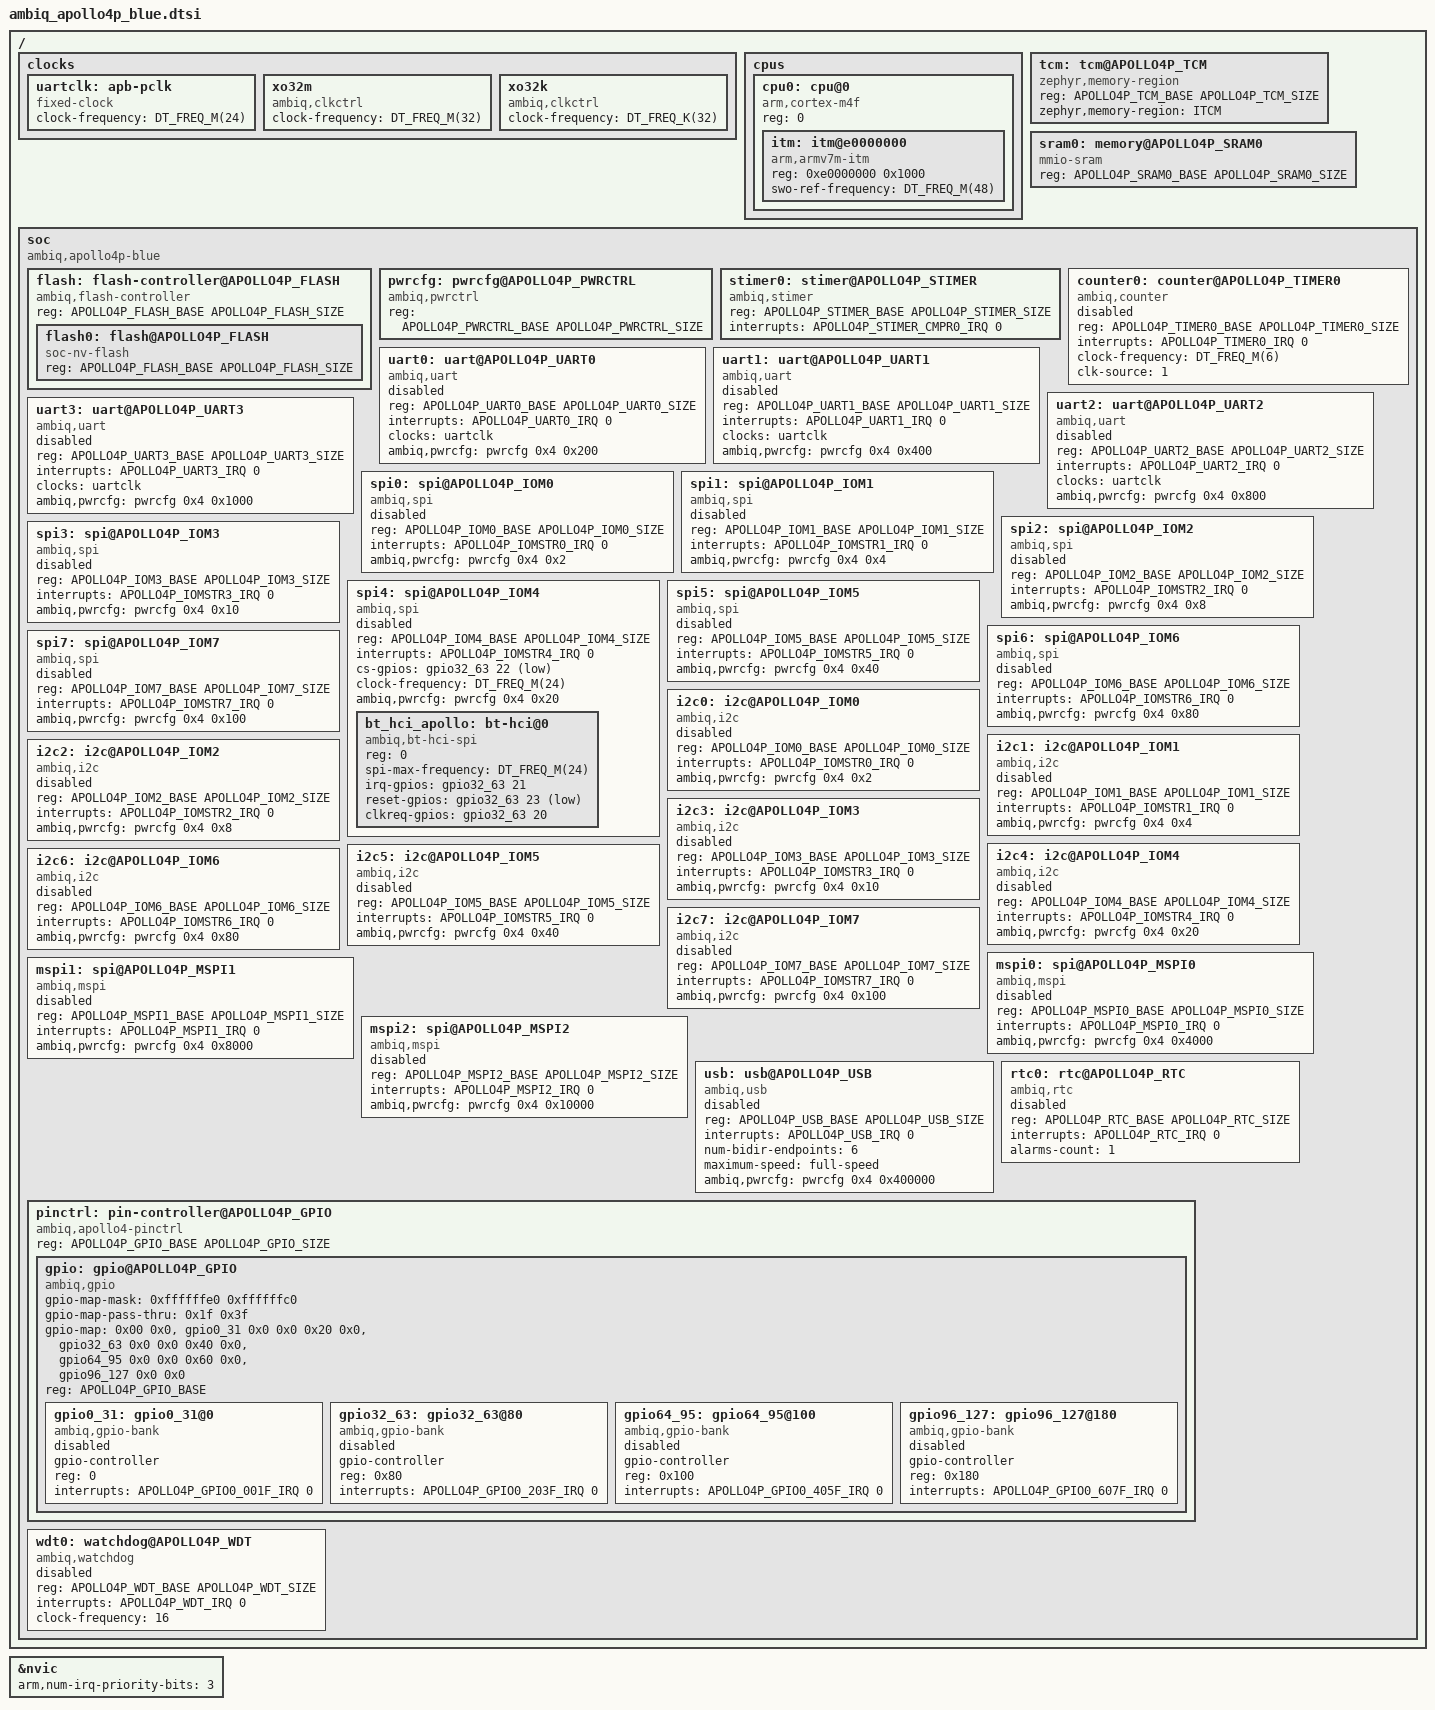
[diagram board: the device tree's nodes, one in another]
/* SPDX-License-Identifier: Apache-2.0 */

#include <arm/armv7-m.dtsi>
#include <mem.h>
#include <freq.h>
#include <apollo4p/am_apollo4p.h>
#include <zephyr/dt-bindings/i2c/i2c.h>
#include <zephyr/dt-bindings/gpio/gpio.h>

/ {
	clocks {
		uartclk: apb-pclk {
			compatible = "fixed-clock";
			clock-frequency = <DT_FREQ_M(24)>;
			#clock-cells = <0>;
		};
		xo32m: xo32m {
			compatible = "ambiq,clkctrl";
			clock-frequency = <DT_FREQ_M(32)>;
			#clock-cells = <1>;
		};
		xo32k: xo32k {
			compatible = "ambiq,clkctrl";
			clock-frequency = <DT_FREQ_K(32)>;
			#clock-cells = <1>;
		};
	};

	cpus {
		#address-cells = <1>;
		#size-cells = <0>;

		cpu0: cpu@0 {
			compatible = "arm,cortex-m4f";
			reg = <0>;
			#address-cells = <1>;
			#size-cells = <1>;

			itm: itm@e0000000 {
				compatible = "arm,armv7m-itm";
				reg = <0xe0000000 0x1000>;
				swo-ref-frequency = <DT_FREQ_M(48)>;
			};
		};
	};

	/* TCM */
	tcm: tcm@APOLLO4P_TCM {
		compatible = "zephyr,memory-region";
		reg = <APOLLO4P_TCM_BASE APOLLO4P_TCM_SIZE>;
		zephyr,memory-region = "ITCM";
	};

	/* SRAM */
	sram0: memory@APOLLO4P_SRAM0 {
		compatible = "mmio-sram";
		reg = <APOLLO4P_SRAM0_BASE APOLLO4P_SRAM0_SIZE>;
	};

	soc {
		compatible = "ambiq,apollo4p-blue", "ambiq,apollo4x", "simple-bus";

		flash: flash-controller@APOLLO4P_FLASH {
			compatible = "ambiq,flash-controller";
			reg = <APOLLO4P_FLASH_BASE APOLLO4P_FLASH_SIZE>;

			#address-cells = <1>;
			#size-cells = <1>;

			/* MRAM region */
			flash0: flash@APOLLO4P_FLASH {
				compatible = "soc-nv-flash";
				reg = <APOLLO4P_FLASH_BASE APOLLO4P_FLASH_SIZE>;
			};
		};

		pwrcfg: pwrcfg@APOLLO4P_PWRCTRL {
			compatible = "ambiq,pwrctrl";
			reg = <APOLLO4P_PWRCTRL_BASE APOLLO4P_PWRCTRL_SIZE>;
			#pwrcfg-cells = <2>;
		};

		stimer0: stimer@APOLLO4P_STIMER {
			compatible = "ambiq,stimer";
			reg = <APOLLO4P_STIMER_BASE APOLLO4P_STIMER_SIZE>;
			interrupts = <APOLLO4P_STIMER_CMPR0_IRQ 0>;
			status = "okay";
		};

		counter0: counter@APOLLO4P_TIMER0 {
			compatible = "ambiq,counter";
			reg = <APOLLO4P_TIMER0_BASE APOLLO4P_TIMER0_SIZE>;
			interrupts = <APOLLO4P_TIMER0_IRQ 0>;
			clock-frequency = <DT_FREQ_M(6)>;
			clk-source = <1>;
			status = "disabled";
		};

		uart0: uart@APOLLO4P_UART0 {
			compatible = "ambiq,uart", "arm,pl011";
			reg = <APOLLO4P_UART0_BASE APOLLO4P_UART0_SIZE>;
			interrupts = <APOLLO4P_UART0_IRQ 0>;
			interrupt-names = "UART0";
			status = "disabled";
			clocks = <&uartclk>;
			ambiq,pwrcfg = <&pwrcfg 0x4 0x200>;
		};
		uart1: uart@APOLLO4P_UART1 {
			compatible = "ambiq,uart", "arm,pl011";
			reg = <APOLLO4P_UART1_BASE APOLLO4P_UART1_SIZE>;
			interrupts = <APOLLO4P_UART1_IRQ 0>;
			interrupt-names = "UART1";
			status = "disabled";
			clocks = <&uartclk>;
			ambiq,pwrcfg = <&pwrcfg 0x4 0x400>;
		};

		uart2: uart@APOLLO4P_UART2 {
			compatible = "ambiq,uart", "arm,pl011";
			reg = <APOLLO4P_UART2_BASE APOLLO4P_UART2_SIZE>;
			interrupts = <APOLLO4P_UART2_IRQ 0>;
			interrupt-names = "UART2";
			status = "disabled";
			clocks = <&uartclk>;
			ambiq,pwrcfg = <&pwrcfg 0x4 0x800>;
		};

		uart3: uart@APOLLO4P_UART3 {
			compatible = "ambiq,uart", "arm,pl011";
			reg = <APOLLO4P_UART3_BASE APOLLO4P_UART3_SIZE>;
			interrupts = <APOLLO4P_UART3_IRQ 0>;
			interrupt-names = "UART3";
			status = "disabled";
			clocks = <&uartclk>;
			ambiq,pwrcfg = <&pwrcfg 0x4 0x1000>;
		};

		spi0: spi@APOLLO4P_IOM0 {
			compatible = "ambiq,spi";
			reg = <APOLLO4P_IOM0_BASE APOLLO4P_IOM0_SIZE>;
			#address-cells = <1>;
			#size-cells = <0>;
			interrupts = <APOLLO4P_IOMSTR0_IRQ 0>;
			status = "disabled";
			ambiq,pwrcfg = <&pwrcfg 0x4 0x2>;
		};

		spi1: spi@APOLLO4P_IOM1 {
			compatible = "ambiq,spi";
			reg = <APOLLO4P_IOM1_BASE APOLLO4P_IOM1_SIZE>;
			#address-cells = <1>;
			#size-cells = <0>;
			interrupts = <APOLLO4P_IOMSTR1_IRQ 0>;
			status = "disabled";
			ambiq,pwrcfg = <&pwrcfg 0x4 0x4>;
		};

		spi2: spi@APOLLO4P_IOM2 {
			compatible = "ambiq,spi";
			reg = <APOLLO4P_IOM2_BASE APOLLO4P_IOM2_SIZE>;
			#address-cells = <1>;
			#size-cells = <0>;
			interrupts = <APOLLO4P_IOMSTR2_IRQ 0>;
			status = "disabled";
			ambiq,pwrcfg = <&pwrcfg 0x4 0x8>;
		};

		spi3: spi@APOLLO4P_IOM3 {
			compatible = "ambiq,spi";
			reg = <APOLLO4P_IOM3_BASE APOLLO4P_IOM3_SIZE>;
			#address-cells = <1>;
			#size-cells = <0>;
			interrupts = <APOLLO4P_IOMSTR3_IRQ 0>;
			status = "disabled";
			ambiq,pwrcfg = <&pwrcfg 0x4 0x10>;
		};

		spi4: spi@APOLLO4P_IOM4 {
			/* IOM4 works as SPI and is wired internally for BLE HCI. */
			compatible = "ambiq,spi";
			reg = <APOLLO4P_IOM4_BASE APOLLO4P_IOM4_SIZE>;
			#address-cells = <1>;
			#size-cells = <0>;
			interrupts = <APOLLO4P_IOMSTR4_IRQ 0>;
			cs-gpios = <&gpio32_63 22 (GPIO_ACTIVE_LOW | GPIO_PULL_UP)>;
			clock-frequency = <DT_FREQ_M(24)>;
			status = "disabled";
			ambiq,pwrcfg = <&pwrcfg 0x4 0x20>;

			bt_hci_apollo: bt-hci@0 {
				compatible = "ambiq,bt-hci-spi";
				reg = <0>;
				spi-max-frequency = <DT_FREQ_M(24)>;
				irq-gpios = <&gpio32_63 21 GPIO_ACTIVE_HIGH>;
				reset-gpios = <&gpio32_63 23 GPIO_ACTIVE_LOW>;
				clkreq-gpios = <&gpio32_63 20 GPIO_ACTIVE_HIGH>;
			};
		};

		spi5: spi@APOLLO4P_IOM5 {
			compatible = "ambiq,spi";
			reg = <APOLLO4P_IOM5_BASE APOLLO4P_IOM5_SIZE>;
			#address-cells = <1>;
			#size-cells = <0>;
			interrupts = <APOLLO4P_IOMSTR5_IRQ 0>;
			status = "disabled";
			ambiq,pwrcfg = <&pwrcfg 0x4 0x40>;
		};

		spi6: spi@APOLLO4P_IOM6 {
			compatible = "ambiq,spi";
			reg = <APOLLO4P_IOM6_BASE APOLLO4P_IOM6_SIZE>;
			#address-cells = <1>;
			#size-cells = <0>;
			interrupts = <APOLLO4P_IOMSTR6_IRQ 0>;
			status = "disabled";
			ambiq,pwrcfg = <&pwrcfg 0x4 0x80>;
		};

		spi7: spi@APOLLO4P_IOM7 {
			compatible = "ambiq,spi";
			reg = <APOLLO4P_IOM7_BASE APOLLO4P_IOM7_SIZE>;
			#address-cells = <1>;
			#size-cells = <0>;
			interrupts = <APOLLO4P_IOMSTR7_IRQ 0>;
			status = "disabled";
			ambiq,pwrcfg = <&pwrcfg 0x4 0x100>;
		};

		i2c0: i2c@APOLLO4P_IOM0 {
			compatible = "ambiq,i2c";
			reg = <APOLLO4P_IOM0_BASE APOLLO4P_IOM0_SIZE>;
			#address-cells = <1>;
			#size-cells = <0>;
			interrupts = <APOLLO4P_IOMSTR0_IRQ 0>;
			status = "disabled";
			ambiq,pwrcfg = <&pwrcfg 0x4 0x2>;
		};

		i2c1: i2c@APOLLO4P_IOM1 {
			compatible = "ambiq,i2c";
			reg = <APOLLO4P_IOM1_BASE APOLLO4P_IOM1_SIZE>;
			#address-cells = <1>;
			#size-cells = <0>;
			interrupts = <APOLLO4P_IOMSTR1_IRQ 0>;
			status = "disabled";
			ambiq,pwrcfg = <&pwrcfg 0x4 0x4>;
		};

		i2c2: i2c@APOLLO4P_IOM2 {
			compatible = "ambiq,i2c";
			reg = <APOLLO4P_IOM2_BASE APOLLO4P_IOM2_SIZE>;
			#address-cells = <1>;
			#size-cells = <0>;
			interrupts = <APOLLO4P_IOMSTR2_IRQ 0>;
			status = "disabled";
			ambiq,pwrcfg = <&pwrcfg 0x4 0x8>;
		};

		i2c3: i2c@APOLLO4P_IOM3 {
			compatible = "ambiq,i2c";
			reg = <APOLLO4P_IOM3_BASE APOLLO4P_IOM3_SIZE>;
			#address-cells = <1>;
			#size-cells = <0>;
			interrupts = <APOLLO4P_IOMSTR3_IRQ 0>;
			status = "disabled";
			ambiq,pwrcfg = <&pwrcfg 0x4 0x10>;
		};

		i2c4: i2c@APOLLO4P_IOM4 {
			compatible = "ambiq,i2c";
			reg = <APOLLO4P_IOM4_BASE APOLLO4P_IOM4_SIZE>;
			#address-cells = <1>;
			#size-cells = <0>;
			interrupts = <APOLLO4P_IOMSTR4_IRQ 0>;
			status = "disabled";
			ambiq,pwrcfg = <&pwrcfg 0x4 0x20>;
		};

		i2c5: i2c@APOLLO4P_IOM5 {
			compatible = "ambiq,i2c";
			reg = <APOLLO4P_IOM5_BASE APOLLO4P_IOM5_SIZE>;
			#address-cells = <1>;
			#size-cells = <0>;
			interrupts = <APOLLO4P_IOMSTR5_IRQ 0>;
			status = "disabled";
			ambiq,pwrcfg = <&pwrcfg 0x4 0x40>;
		};

		i2c6: i2c@APOLLO4P_IOM6 {
			compatible = "ambiq,i2c";
			reg = <APOLLO4P_IOM6_BASE APOLLO4P_IOM6_SIZE>;
			#address-cells = <1>;
			#size-cells = <0>;
			interrupts = <APOLLO4P_IOMSTR6_IRQ 0>;
			status = "disabled";
			ambiq,pwrcfg = <&pwrcfg 0x4 0x80>;
		};

		i2c7: i2c@APOLLO4P_IOM7 {
			compatible = "ambiq,i2c";
			reg = <APOLLO4P_IOM7_BASE APOLLO4P_IOM7_SIZE>;
			#address-cells = <1>;
			#size-cells = <0>;
			interrupts = <APOLLO4P_IOMSTR7_IRQ 0>;
			status = "disabled";
			ambiq,pwrcfg = <&pwrcfg 0x4 0x100>;
		};

		mspi0: spi@APOLLO4P_MSPI0 {
			compatible = "ambiq,mspi";
			reg = <APOLLO4P_MSPI0_BASE APOLLO4P_MSPI0_SIZE>;
			interrupts = <APOLLO4P_MSPI0_IRQ 0>;
			#address-cells = <1>;
			#size-cells = <0>;
			status = "disabled";
			ambiq,pwrcfg = <&pwrcfg 0x4 0x4000>;
		};

		mspi1: spi@APOLLO4P_MSPI1 {
			compatible = "ambiq,mspi";
			reg = <APOLLO4P_MSPI1_BASE APOLLO4P_MSPI1_SIZE>;
			interrupts = <APOLLO4P_MSPI1_IRQ 0>;
			#address-cells = <1>;
			#size-cells = <0>;
			status = "disabled";
			ambiq,pwrcfg = <&pwrcfg 0x4 0x8000>;
		};

		mspi2: spi@APOLLO4P_MSPI2 {
			compatible = "ambiq,mspi";
			reg = <APOLLO4P_MSPI2_BASE APOLLO4P_MSPI2_SIZE>;
			interrupts = <APOLLO4P_MSPI2_IRQ 0>;
			#address-cells = <1>;
			#size-cells = <0>;
			status = "disabled";
			ambiq,pwrcfg = <&pwrcfg 0x4 0x10000>;
		};

		usb: usb@APOLLO4P_USB {
			compatible = "ambiq,usb";
			reg = <APOLLO4P_USB_BASE APOLLO4P_USB_SIZE>;
			interrupts = <APOLLO4P_USB_IRQ 0>;
			num-bidir-endpoints = <6>;
			maximum-speed = "full-speed";
			status = "disabled";
			ambiq,pwrcfg = <&pwrcfg 0x4 0x400000>;
		};

		rtc0: rtc@APOLLO4P_RTC {
			compatible = "ambiq,rtc";
			reg = <APOLLO4P_RTC_BASE APOLLO4P_RTC_SIZE>;
			interrupts = <APOLLO4P_RTC_IRQ 0>;
			alarms-count = <1>;
			status = "disabled";
		};

		pinctrl: pin-controller@APOLLO4P_GPIO {
			compatible = "ambiq,apollo4-pinctrl";
			reg = <APOLLO4P_GPIO_BASE APOLLO4P_GPIO_SIZE>;
			#address-cells = <1>;
			#size-cells = <0>;

			gpio: gpio@APOLLO4P_GPIO {
				compatible = "ambiq,gpio";
				gpio-map-mask = <0xffffffe0 0xffffffc0>;
				gpio-map-pass-thru = <0x1f 0x3f>;
				gpio-map = <
					0x00 0x0 &gpio0_31 0x0 0x0
					0x20 0x0 &gpio32_63 0x0 0x0
					0x40 0x0 &gpio64_95 0x0 0x0
					0x60 0x0 &gpio96_127 0x0 0x0
				>;
				reg = <APOLLO4P_GPIO_BASE>;
				#gpio-cells = <2>;
				#address-cells = <1>;
				#size-cells = <0>;
				ranges;

				gpio0_31: gpio0_31@0 {
					compatible = "ambiq,gpio-bank";
					gpio-controller;
					#gpio-cells = <2>;
					reg = <0>;
					interrupts = <APOLLO4P_GPIO0_001F_IRQ 0>;
					status = "disabled";
				};

				gpio32_63: gpio32_63@80 {
					compatible = "ambiq,gpio-bank";
					gpio-controller;
					#gpio-cells = <2>;
					reg = <0x80>;
					interrupts = <APOLLO4P_GPIO0_203F_IRQ 0>;
					status = "disabled";
				};

				gpio64_95: gpio64_95@100 {
					compatible = "ambiq,gpio-bank";
					gpio-controller;
					#gpio-cells = <2>;
					reg = <0x100>;
					interrupts = <APOLLO4P_GPIO0_405F_IRQ 0>;
					status = "disabled";
				};

				gpio96_127: gpio96_127@180 {
					compatible = "ambiq,gpio-bank";
					gpio-controller;
					#gpio-cells = <2>;
					reg = <0x180>;
					interrupts = <APOLLO4P_GPIO0_607F_IRQ 0>;
					status = "disabled";
				};
			};
		};

		wdt0: watchdog@APOLLO4P_WDT {
			compatible = "ambiq,watchdog";
			reg = <APOLLO4P_WDT_BASE APOLLO4P_WDT_SIZE>;
			interrupts = <APOLLO4P_WDT_IRQ 0>;
			clock-frequency = <16>;
			status = "disabled";
		};
	};
};

&nvic {
	arm,num-irq-priority-bits = <3>;
};
